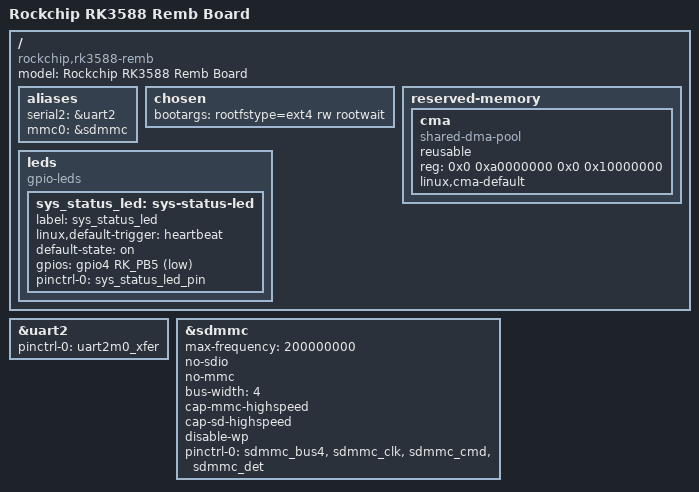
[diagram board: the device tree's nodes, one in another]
/dts-v1/;							//定义了dts的版本,必须项

#include "rk3588s_.dtsi"


/ {
	model = "Rockchip RK3588 Remb Board";
	compatible = "rockchip,rk3588-remb", "rockchip,rk3588";

	aliases {
		serial2 = &uart2;
		mmc0 = &sdmmc;
	};

	chosen: chosen {
		bootargs = "rootfstype=ext4 rw rootwait";
	};

	reserved-memory {
		#address-cells = <2>;
		#size-cells = <2>;
		ranges;

		cma {
			compatible = "shared-dma-pool";
			reusable;
			reg = <0x0 0xa0000000 0x0 0x10000000>;
			linux,cma-default;
		};
	};

	leds: leds {
		status = "okay";
		compatible = "gpio-leds";

		sys_status_led: sys-status-led {
			label = "sys_status_led";
			linux,default-trigger = "heartbeat";
			default-state = "on";
			gpios = <&gpio4 RK_PB5 GPIO_ACTIVE_LOW>;
			pinctrl-names = "default";
			pinctrl-0 = <&sys_status_led_pin>;
		};
	};




};

&uart2 {
	pinctrl-0 = <&uart2m0_xfer>;
	status = "okay";
};

&sdmmc {
	max-frequency = <200000000>;
	no-sdio;
	no-mmc;
	bus-width = <4>;
	cap-mmc-highspeed;
	cap-sd-highspeed;
	disable-wp;
	//sd-uhs-sdr104;
	//vmmc-supply = <&vcc_3v3_sd_s3>;
	//vqmmc-supply = <&vccio_sd_s0>;
	pinctrl-names = "default";
	pinctrl-0 = <&sdmmc_bus4 &sdmmc_clk &sdmmc_cmd &sdmmc_det>;
	status = "okay";
};
